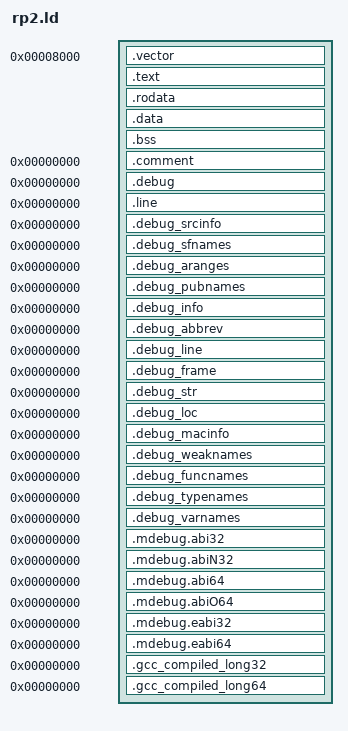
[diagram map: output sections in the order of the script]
/*
 *  $Id: rp2.ld 679 2016-10-17 00:00:00Z azo $
 */

OUTPUT_FORMAT("elf32-littlearm", "elf32-bigarm","elf32-littlearm") 
OUTPUT_ARCH(arm)

PROVIDE(hardware_init_hook = 0);
PROVIDE(software_init_hook = 0);
PROVIDE(software_term_hook = 0);
STARTUP(start.o)

SECTIONS {
	. = 0x8000;
	.vector ALIGN(4) : {
		__start_vector = .;
		*(.vector)
                *(vector)
		__end_vector = .;
	}

	.text ALIGN(4) : {
		__start_text = .;
		*(.text)
		*(.glue_7t)
		*(.glue_7)
		__end_kernel = .;
	}
	_etext = .;
	PROVIDE(etext = .);

	.rodata ALIGN(4) : {
		__start_rodata = .;
		*(.rodata)
		__end_rodata = .;
	}

	. = ALIGN(4);
	__start_idata = .;
	__idata_start = .;
	.data : AT(__start_idata) {
		__start_data = .;
		__data_start = .;
		*(.data)
		__end_data = .;
	}
	__end_idata = __start_idata + SIZEOF(.data);
	__idata_end = __start_idata + SIZEOF(.data);
	_edata = .;
	PROVIDE(edata = .);

	.bss ALIGN(4) : {
		__start_bss = .;
		__bss_start = .;
		__bss_start__ = .;
		*(.bss)
		*(COMMON)
		__end_bss = .;
		__bss_end = .;
		__bss_end__ = .;
	}

	. = ALIGN(4);
	_end = .;
	PROVIDE(end = .);
	.comment 0 : { *(.comment) }	

	/*
	 *  DWARF debug sections.
	 *  Symbols in the DWARF debugging sections are relative to
	 *  the beginning of the section so we begin them at 0.
	 */

	/* DWARF 1 */
	.debug			0 : { *(.debug) }
	.line			0 : { *(.line) }

	/* GNU DWARF 1 extensions */
	.debug_srcinfo	0 : { *(.debug_srcinfo) }
	.debug_sfnames	0 : { *(.debug_sfnames) }

	/* DWARF 1.1 and DWARF 2 */
	.debug_aranges	0 : { *(.debug_aranges) }
	.debug_pubnames	0 : { *(.debug_pubnames) }

	/* DWARF 2 */
	.debug_info		0 : { *(.debug_info) }
	.debug_abbrev	0 : { *(.debug_abbrev) }
	.debug_line		0 : { *(.debug_line) }
	.debug_frame	0 : { *(.debug_frame) }
	.debug_str		0 : { *(.debug_str) }
	.debug_loc		0 : { *(.debug_loc) }
	.debug_macinfo	0 : { *(.debug_macinfo) }

	/* SGI/MIPS DWARF 2 extensions */
	.debug_weaknames 0 : { *(.debug_weaknames) }
	.debug_funcnames 0 : { *(.debug_funcnames) }
	.debug_typenames 0 : { *(.debug_typenames) }
	.debug_varnames  0 : { *(.debug_varnames) }

	/* Special sections generated by gcc */
	/* Newer GNU linkers strip by default */
	.mdebug.abi32	0 : { KEEP(*(.mdebug.abi32)) }
	.mdebug.abiN32	0 : { KEEP(*(.mdebug.abiN32)) }
	.mdebug.abi64	0 : { KEEP(*(.mdebug.abi64)) }
	.mdebug.abiO64	0 : { KEEP(*(.mdebug.abiO64)) }
	.mdebug.eabi32	0 : { KEEP(*(.mdebug.eabi32)) }
	.mdebug.eabi64	0 : { KEEP(*(.mdebug.eabi64)) }
	.gcc_compiled_long32	0 : { KEEP(*(.gcc_compiled_long32)) }
	.gcc_compiled_long64	0 : { KEEP(*(.gcc_compiled_long64)) }
}	
